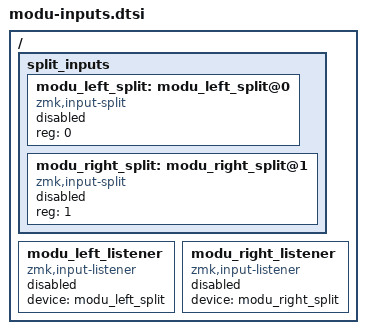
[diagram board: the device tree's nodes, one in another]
/*
 * Copyright (c) 2026 EKS Inc. Created by Ryu.
 * SPDX-License-Identifier: LicenseRef-EKS-NonCommercial-1.0
 * Unofficial Obrey dongle adaptation; see root NOTICE.md.
 */

/* Two unique channel IDs. All three devices include this same file.
 * This is separate from the original two-part trackball_split@0, which is
 * explicitly disabled on both dongle peripherals.
 */
/ {
    split_inputs {
        #address-cells = <1>;
        #size-cells = <0>;
        modu_left_split: modu_left_split@0 {
            compatible = "zmk,input-split";
            reg = <0>;
            status = "disabled";
        };
        modu_right_split: modu_right_split@1 {
            compatible = "zmk,input-split";
            reg = <1>;
            status = "disabled";
        };
    };
    modu_left_listener: modu_left_listener {
        compatible = "zmk,input-listener";
        device = <&modu_left_split>;
        status = "disabled";
    };
    modu_right_listener: modu_right_listener {
        compatible = "zmk,input-listener";
        device = <&modu_right_split>;
        status = "disabled";
    };
};
